# TM4C123AH6PM register map
Vendor: Texas Instruments; File version: 11073
CPU: CM4 r1p2, little endian, no MPU, no FPU, 0x3 interrupt priority bits, 0x0 interrupts
Registers are 32-bit, read-write, no defined reset value unless marked. A register's access mark holds for its fields unless they carry their own. Offsets are from the block's base; [hi:lo] are bit positions; {n}, {i} and the like mark numbered series.

## SYSEXC — Register map for SYSEXC peripheral
Base 0x400F9000; register names take the prefix SYSEXC
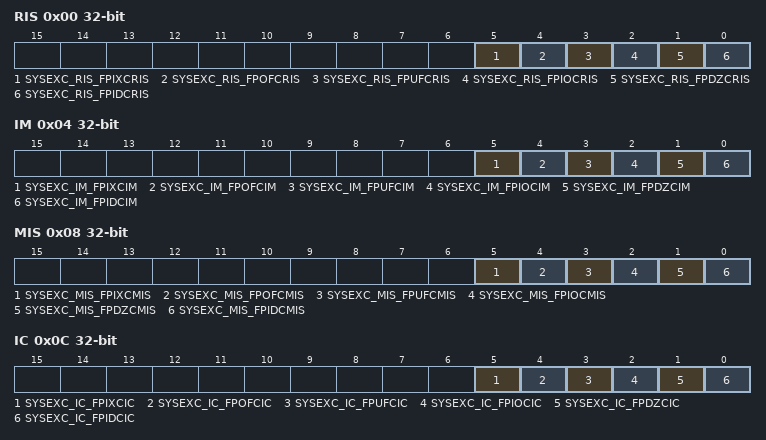
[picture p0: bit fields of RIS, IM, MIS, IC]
0x00 RIS — System Exception Raw Interrupt Status
  [5] SYSEXC_RIS_FPIXCRIS — Floating-Point Inexact Exception Raw Interrupt Status
  [4] SYSEXC_RIS_FPOFCRIS — Floating-Point Overflow Exception Raw Interrupt Status
  [3] SYSEXC_RIS_FPUFCRIS — Floating-Point Underflow Exception Raw Interrupt Status
  [2] SYSEXC_RIS_FPIOCRIS — Floating-Point Invalid Operation Raw Interrupt Status
  [1] SYSEXC_RIS_FPDZCRIS — Floating-Point Divide By 0 Exception Raw Interrupt Status
  [0] SYSEXC_RIS_FPIDCRIS — Floating-Point Input Denormal Exception Raw Interrupt Status
0x04 IM — System Exception Interrupt Mask
  [5] SYSEXC_IM_FPIXCIM — Floating-Point Inexact Exception Interrupt Mask
  [4] SYSEXC_IM_FPOFCIM — Floating-Point Overflow Exception Interrupt Mask
  [3] SYSEXC_IM_FPUFCIM — Floating-Point Underflow Exception Interrupt Mask
  [2] SYSEXC_IM_FPIOCIM — Floating-Point Invalid Operation Interrupt Mask
  [1] SYSEXC_IM_FPDZCIM — Floating-Point Divide By 0 Exception Interrupt Mask
  [0] SYSEXC_IM_FPIDCIM — Floating-Point Input Denormal Exception Interrupt Mask
0x08 MIS — System Exception Masked Interrupt Status
  [5] SYSEXC_MIS_FPIXCMIS — Floating-Point Inexact Exception Masked Interrupt Status
  [4] SYSEXC_MIS_FPOFCMIS — Floating-Point Overflow Exception Masked Interrupt Status
  [3] SYSEXC_MIS_FPUFCMIS — Floating-Point Underflow Exception Masked Interrupt Status
  [2] SYSEXC_MIS_FPIOCMIS — Floating-Point Invalid Operation Masked Interrupt Status
  [1] SYSEXC_MIS_FPDZCMIS — Floating-Point Divide By 0 Exception Masked Interrupt Status
  [0] SYSEXC_MIS_FPIDCMIS — Floating-Point Input Denormal Exception Masked Interrupt Status
0x0C IC wo — System Exception Interrupt Clear
  [5] SYSEXC_IC_FPIXCIC — Floating-Point Inexact Exception Interrupt Clear
  [4] SYSEXC_IC_FPOFCIC — Floating-Point Overflow Exception Interrupt Clear
  [3] SYSEXC_IC_FPUFCIC — Floating-Point Underflow Exception Interrupt Clear
  [2] SYSEXC_IC_FPIOCIC — Floating-Point Invalid Operation Interrupt Clear
  [1] SYSEXC_IC_FPDZCIC — Floating-Point Divide By 0 Exception Interrupt Clear
  [0] SYSEXC_IC_FPIDCIC — Floating-Point Input Denormal Exception Interrupt Clear

## UDMA — Register map for UDMA peripheral
Base 0x400FF000; register names take the prefix UDMA
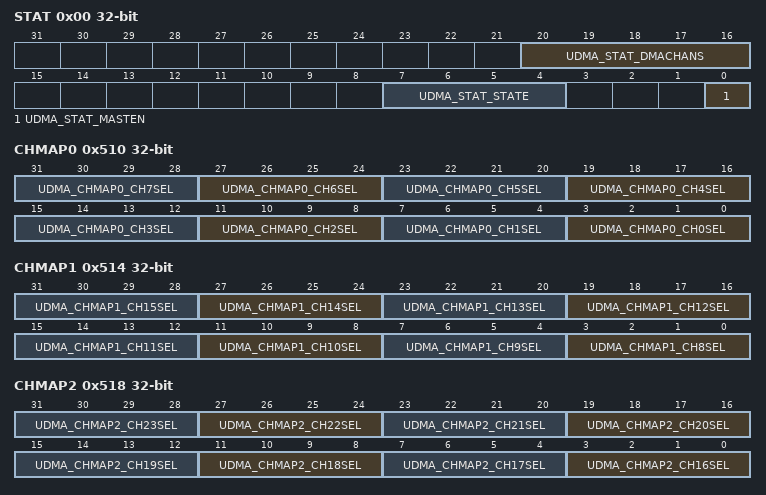
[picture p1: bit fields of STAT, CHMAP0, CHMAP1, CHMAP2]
0x00 STAT — DMA Status
  [20:16] UDMA_STAT_DMACHANS — Available uDMA Channels Minus 1
  [7:4] UDMA_STAT_STATE — Control State Machine Status
    0=UDMA_STAT_STATE_IDLE (Idle); 1=UDMA_STAT_STATE_RD_CTRL (Reading channel controller data); 2=UDMA_STAT_STATE_RD_SRCENDP (Reading source end pointer); 3=UDMA_STAT_STATE_RD_DSTENDP (Reading destination end pointer); 4=UDMA_STAT_STATE_RD_SRCDAT (Reading source data); 5=UDMA_STAT_STATE_WR_DSTDAT (Writing destination data); 6=UDMA_STAT_STATE_WAIT (Waiting for uDMA request to clear); 7=UDMA_STAT_STATE_WR_CTRL (Writing channel controller data); 8=UDMA_STAT_STATE_STALL (Stalled); 9=UDMA_STAT_STATE_DONE (Done); 10=UDMA_STAT_STATE_UNDEF (Undefined)
  [0] UDMA_STAT_MASTEN — Master Enable Status
0x04 CFG wo — DMA Configuration
  [0] UDMA_CFG_MASTEN — Controller Master Enable
0x08 CTLBASE — DMA Channel Control Base Pointer
  [31:10] UDMA_CTLBASE_ADDR — Channel Control Base Address
0x0C ALTBASE — DMA Alternate Channel Control Base Pointer
  [31:0] UDMA_ALTBASE_ADDR — Alternate Channel Address Pointer
0x10 WAITSTAT — DMA Channel Wait-on-Request Status
  [31:0] UDMA_WAITSTAT_WAITREQ — Channel [n] Wait Status
0x14 SWREQ wo — DMA Channel Software Request
  [31:0] UDMA_SWREQ — Channel [n] Software Request
0x18 USEBURSTSET — DMA Channel Useburst Set
  [31:0] UDMA_USEBURSTSET_SET — Channel [n] Useburst Set
0x1C USEBURSTCLR wo — DMA Channel Useburst Clear
  [31:0] UDMA_USEBURSTCLR_CLR — Channel [n] Useburst Clear
0x20 REQMASKSET — DMA Channel Request Mask Set
  [31:0] UDMA_REQMASKSET_SET — Channel [n] Request Mask Set
0x24 REQMASKCLR wo — DMA Channel Request Mask Clear
  [31:0] UDMA_REQMASKCLR_CLR — Channel [n] Request Mask Clear
0x28 ENASET — DMA Channel Enable Set
  [31:0] UDMA_ENASET_SET — Channel [n] Enable Set
0x2C ENACLR wo — DMA Channel Enable Clear
  [31:0] UDMA_ENACLR_CLR — Clear Channel [n] Enable Clear
0x30 ALTSET — DMA Channel Primary Alternate Set
  [31:0] UDMA_ALTSET_SET — Channel [n] Alternate Set
0x34 ALTCLR wo — DMA Channel Primary Alternate Clear
  [31:0] UDMA_ALTCLR_CLR — Channel [n] Alternate Clear
0x38 PRIOSET — DMA Channel Priority Set
  [31:0] UDMA_PRIOSET_SET — Channel [n] Priority Set
0x3C PRIOCLR wo — DMA Channel Priority Clear
  [31:0] UDMA_PRIOCLR_CLR — Channel [n] Priority Clear
0x4C ERRCLR — DMA Bus Error Clear
  [0] UDMA_ERRCLR_ERRCLR — uDMA Bus Error Status
0x500 CHASGN — DMA Channel Assignment
  [31:0] UDMA_CHASGN — Channel [n] Assignment Select
    0=UDMA_CHASGN_PRIMARY (Use the primary channel assignment); 1=UDMA_CHASGN_SECONDARY (Use the secondary channel assignment)
0x504 CHIS — DMA Channel Interrupt Status
  [31:0] UDMA_CHIS — Channel [n] Interrupt Status
0x510 CHMAP0 — DMA Channel Map Select 0
  [4n+3:4n] UDMA_CHMAP0_CH{n}SEL (n=0..7) — uDMA Channel {n} Source Select
0x514 CHMAP1 — DMA Channel Map Select 1
  [4n-29:4n-32] UDMA_CHMAP1_CH{n}SEL (n=8..15) — uDMA Channel {n} Source Select
0x518 CHMAP2 — DMA Channel Map Select 2
  [4n-61:4n-64] UDMA_CHMAP2_CH{n}SEL (n=16..23) — uDMA Channel {n} Source Select
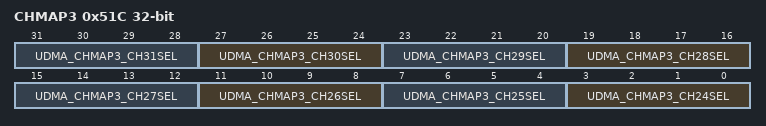
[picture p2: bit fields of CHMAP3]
0x51C CHMAP3 — DMA Channel Map Select 3
  [4n-93:4n-96] UDMA_CHMAP3_CH{n}SEL (n=24..31) — uDMA Channel {n} Source Select
